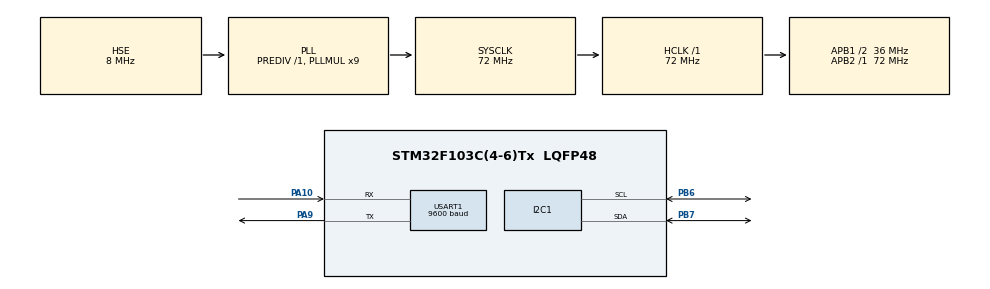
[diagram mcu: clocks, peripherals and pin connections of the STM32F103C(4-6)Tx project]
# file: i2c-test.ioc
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Mcu.Family=STM32F1
Mcu.Name=STM32F103C(4-6)Tx
Mcu.Package=LQFP48
NVIC.PriorityGroup=NVIC_PRIORITYGROUP_4
PA10.Mode=Asynchronous
PA10.Signal=USART1_RX
PA9.Mode=Asynchronous
PA9.Signal=USART1_TX
PB6.GPIO_Pu=GPIO_PULLUP
PB6.GPIO_Speed=GPIO_SPEED_FREQ_MEDIUM
PB6.Mode=I2C
PB6.Signal=I2C1_SCL
PB7.GPIO_Pu=GPIO_PULLUP
PB7.GPIO_Speed=GPIO_SPEED_FREQ_MEDIUM
PB7.Mode=I2C
PB7.Signal=I2C1_SDA
PD0-OSC_IN.Mode=HSE-External-Oscillator
PD0-OSC_IN.Signal=RCC_OSC_IN
PD1-OSC_OUT.Mode=HSE-External-Oscillator
PD1-OSC_OUT.Signal=RCC_OSC_OUT
ProjectManager.HeapSize=0x200
ProjectManager.StackSize=0x400
ProjectManager.TargetToolchain=MDK-ARM V5.32
RCC.AHBFreq_Value=72000000
RCC.APB1CLKDivider=RCC_HCLK_DIV2
RCC.APB1Freq_Value=36000000
RCC.APB1TimFreq_Value=72000000
RCC.APB2Freq_Value=72000000
RCC.APB2TimFreq_Value=72000000
RCC.HCLKFreq_Value=72000000
RCC.PLLMUL=RCC_PLL_MUL9
RCC.PLLSourceVirtual=RCC_PLLSOURCE_HSE
RCC.SYSCLKFreq_VALUE=72000000
RCC.SYSCLKSource=RCC_SYSCLKSOURCE_PLLCLK
RCC.USBFreq_Value=72000000
USART1.BaudRate=9600
USART1.VirtualMode=VM_ASYNC
VP_SYS_VS_ND.Mode=No_Debug
board=custom

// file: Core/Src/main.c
/* USER CODE BEGIN Header */
/**
  ******************************************************************************
  * @file           : main.c
  * @brief          : Main program body
  ******************************************************************************
  * @attention
  *
  * Copyright (c) 2025 STMicroelectronics.
  * All rights reserved.
  *
  * This software is licensed under terms that can be found in the LICENSE file
  * in the root directory of this software component.
  * If no LICENSE file comes with this software, it is provided AS-IS.
  *
  ******************************************************************************
  */
/* USER CODE END Header */
#include "main.h"

/* USER CODE BEGIN Includes */
#include "si7021.h"
#include <string.h> // strlen fonksiyonu i�in eklendi
#include <stdio.h>
/* USER CODE END Includes */

I2C_HandleTypeDef hi2c1;

UART_HandleTypeDef huart1;

void SystemClock_Config(void);
static void MX_GPIO_Init(void);
static void MX_I2C1_Init(void);
static void MX_USART1_UART_Init(void);

int main(void)
{

  /* MCU Configuration--------------------------------------------------------*/

  /* Reset of all peripherals, Initializes the Flash interface and the Systick. */
  HAL_Init();

  /* Configure the system clock */
  SystemClock_Config();

  /* Initialize all configured peripherals */
  MX_GPIO_Init();
  MX_I2C1_Init();
  MX_USART1_UART_Init();
  /* USER CODE BEGIN 2 */
	uint32_t temp=0, humidity=0;
	char data[50];
  /* USER CODE END 2 */

  /* Infinite loop */
  while (1)
  {

    /* USER CODE BEGIN 3 */
		temp=	si7021_measure_temperature(&hi2c1);
		humidity= si7021_measure_humidity(&hi2c1);
		sprintf(data, "%d - %d\n",temp,humidity);

		HAL_UART_Transmit(&huart1, (uint8_t *)data, strlen(data), HAL_MAX_DELAY);

		HAL_Delay(1000); // 1 saniye gecikme
  }
  /* USER CODE END 3 */
}

void SystemClock_Config(void)
{
  RCC_OscInitTypeDef RCC_OscInitStruct = {0};
  RCC_ClkInitTypeDef RCC_ClkInitStruct = {0};

  /** Initializes the RCC Oscillators according to the specified parameters
  * in the RCC_OscInitTypeDef structure.
  */
  RCC_OscInitStruct.OscillatorType = RCC_OSCILLATORTYPE_HSE;
  RCC_OscInitStruct.HSEState = RCC_HSE_ON;
  RCC_OscInitStruct.HSEPredivValue = RCC_HSE_PREDIV_DIV1;
  RCC_OscInitStruct.HSIState = RCC_HSI_ON;
  RCC_OscInitStruct.PLL.PLLState = RCC_PLL_ON;
  RCC_OscInitStruct.PLL.PLLSource = RCC_PLLSOURCE_HSE;
  RCC_OscInitStruct.PLL.PLLMUL = RCC_PLL_MUL9;
  if (HAL_RCC_OscConfig(&RCC_OscInitStruct) != HAL_OK)
  {
    Error_Handler();
  }

  /** Initializes the CPU, AHB and APB buses clocks
  */
  RCC_ClkInitStruct.ClockType = RCC_CLOCKTYPE_HCLK|RCC_CLOCKTYPE_SYSCLK
                              |RCC_CLOCKTYPE_PCLK1|RCC_CLOCKTYPE_PCLK2;
  RCC_ClkInitStruct.SYSCLKSource = RCC_SYSCLKSOURCE_PLLCLK;
  RCC_ClkInitStruct.AHBCLKDivider = RCC_SYSCLK_DIV1;
  RCC_ClkInitStruct.APB1CLKDivider = RCC_HCLK_DIV2;
  RCC_ClkInitStruct.APB2CLKDivider = RCC_HCLK_DIV1;

  if (HAL_RCC_ClockConfig(&RCC_ClkInitStruct, FLASH_LATENCY_2) != HAL_OK)
  {
    Error_Handler();
  }
}

static void MX_I2C1_Init(void)
{

  hi2c1.Instance = I2C1;
  hi2c1.Init.ClockSpeed = 100000;
  hi2c1.Init.DutyCycle = I2C_DUTYCYCLE_2;
  hi2c1.Init.OwnAddress1 = 0;
  hi2c1.Init.AddressingMode = I2C_ADDRESSINGMODE_7BIT;
  hi2c1.Init.DualAddressMode = I2C_DUALADDRESS_DISABLE;
  hi2c1.Init.OwnAddress2 = 0;
  hi2c1.Init.GeneralCallMode = I2C_GENERALCALL_DISABLE;
  hi2c1.Init.NoStretchMode = I2C_NOSTRETCH_DISABLE;
  if (HAL_I2C_Init(&hi2c1) != HAL_OK)
  {
    Error_Handler();
  }

}

static void MX_USART1_UART_Init(void)
{

  huart1.Instance = USART1;
  huart1.Init.BaudRate = 9600;
  huart1.Init.WordLength = UART_WORDLENGTH_8B;
  huart1.Init.StopBits = UART_STOPBITS_1;
  huart1.Init.Parity = UART_PARITY_NONE;
  huart1.Init.Mode = UART_MODE_TX_RX;
  huart1.Init.HwFlowCtl = UART_HWCONTROL_NONE;
  huart1.Init.OverSampling = UART_OVERSAMPLING_16;
  if (HAL_UART_Init(&huart1) != HAL_OK)
  {
    Error_Handler();
  }

}

static void MX_GPIO_Init(void)
{

  /* GPIO Ports Clock Enable */
  __HAL_RCC_GPIOD_CLK_ENABLE();
  __HAL_RCC_GPIOA_CLK_ENABLE();
  __HAL_RCC_GPIOB_CLK_ENABLE();

}

void Error_Handler(void)
{
  __disable_irq();
  while (1)
  {
  }
}
